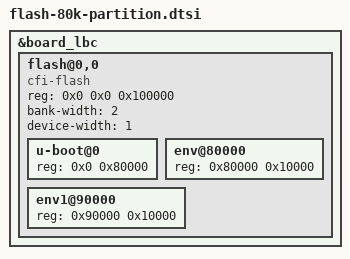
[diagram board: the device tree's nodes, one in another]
&board_lbc {
	flash@0,0 {
		#address-cells = <1>;
		#size-cells = <1>;
		compatible = "cfi-flash";
		reg = <0x0 0x0 0x100000>;
		bank-width = <2>;
		device-width = <1>;

		u-boot@0 {
			reg = <0x0 0x80000>;
		};
		env@80000 {
			reg = <0x80000 0x10000>;
		};
		env1@90000 {
			reg = <0x90000 0x10000>;
		};
	};
};
